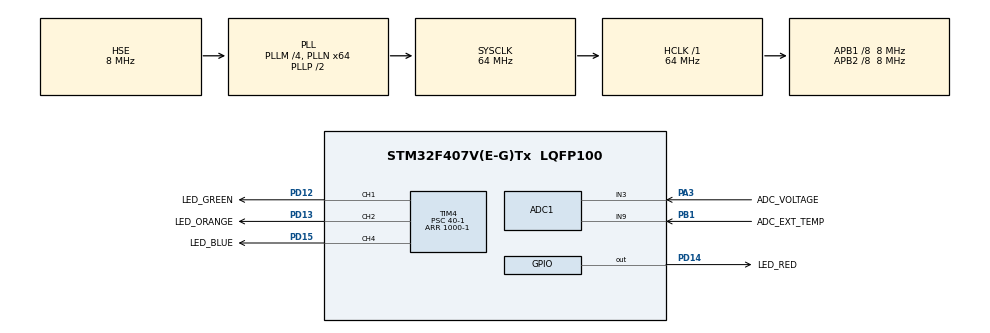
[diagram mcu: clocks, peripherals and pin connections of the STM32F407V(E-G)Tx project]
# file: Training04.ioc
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ADC1.Channel-0\#ChannelRegularConversion=ADC_CHANNEL_3
ADC1.Channel-3\#ChannelRegularConversion=ADC_CHANNEL_TEMPSENSOR
ADC1.Channel-4\#ChannelRegularConversion=ADC_CHANNEL_9
ADC1.ClockPrescaler=ADC_CLOCK_SYNC_PCLK_DIV8
ADC1.ContinuousConvMode=ENABLE
ADC1.EnableAnalogWatchDog=false
ADC1.InjNumberOfConversion=0
ADC1.NbrOfConversion=3
ADC1.NbrOfConversionFlag=1
ADC1.Rank-0\#ChannelRegularConversion=1
ADC1.Rank-3\#ChannelRegularConversion=2
ADC1.Rank-4\#ChannelRegularConversion=3
ADC1.SamplingTime-0\#ChannelRegularConversion=ADC_SAMPLETIME_480CYCLES
ADC1.SamplingTime-3\#ChannelRegularConversion=ADC_SAMPLETIME_56CYCLES
ADC1.SamplingTime-4\#ChannelRegularConversion=ADC_SAMPLETIME_112CYCLES
ADC1.master=1
Mcu.Family=STM32F4
Mcu.Name=STM32F407V(E-G)Tx
Mcu.Package=LQFP100
NVIC.PriorityGroup=NVIC_PRIORITYGROUP_4
NVIC.TIM6_DAC_IRQn=true\:0\:0\:false\:false\:true\:true\:true\:true
PA3.GPIO_Label=ADC_VOLTAGE
PA3.Signal=ADCx_IN3
PB1.GPIO_Label=ADC_EXT_TEMP
PB1.Signal=ADCx_IN9
PD12.GPIO_Label=LED_GREEN
PD12.GPIO_ModeDefaultPP=GPIO_MODE_AF_PP
PD12.GPIO_PuPd=GPIO_PULLDOWN
PD12.GPIO_Speed=GPIO_SPEED_FREQ_HIGH
PD12.Signal=S_TIM4_CH1
PD13.GPIO_Label=LED_ORANGE
PD13.GPIO_ModeDefaultPP=GPIO_MODE_AF_PP
PD13.GPIO_PuPd=GPIO_PULLDOWN
PD13.GPIO_Speed=GPIO_SPEED_FREQ_HIGH
PD13.Signal=S_TIM4_CH2
PD14.GPIO_Label=LED_RED
PD14.Signal=GPIO_Output
PD15.GPIO_Label=LED_BLUE
PD15.GPIO_ModeDefaultPP=GPIO_MODE_AF_PP
PD15.GPIO_PuPd=GPIO_PULLDOWN
PD15.GPIO_Speed=GPIO_SPEED_FREQ_HIGH
PD15.Signal=S_TIM4_CH4
PH0-OSC_IN.Mode=HSE-External-Oscillator
PH0-OSC_IN.Signal=RCC_OSC_IN
PH1-OSC_OUT.Mode=HSE-External-Oscillator
PH1-OSC_OUT.Signal=RCC_OSC_OUT
ProjectManager.HeapSize=0x200
ProjectManager.StackSize=0x400
ProjectManager.TargetToolchain=STM32CubeIDE
RCC.48MHZClocksFreq_Value=32000000
RCC.AHBFreq_Value=64000000
RCC.APB1CLKDivider=RCC_HCLK_DIV8
RCC.APB1Freq_Value=8000000
RCC.APB1TimFreq_Value=16000000
RCC.APB2CLKDivider=RCC_HCLK_DIV8
RCC.APB2Freq_Value=8000000
RCC.APB2TimFreq_Value=16000000
RCC.CortexFreq_Value=64000000
RCC.HCLKFreq_Value=64000000
RCC.HSE_VALUE=8000000
RCC.HSI_VALUE=16000000
RCC.LSE_VALUE=32768
RCC.PLLM=4
RCC.PLLN=64
RCC.PLLSourceVirtual=RCC_PLLSOURCE_HSE
RCC.SYSCLKFreq_VALUE=64000000
RCC.SYSCLKSource=RCC_SYSCLKSOURCE_PLLCLK
RCC.VCOOutputFreq_Value=128000000
SH.ADCx_IN3.0=ADC1_IN3,IN3
SH.ADCx_IN9.0=ADC1_IN9,IN9
SH.S_TIM4_CH1.0=TIM4_CH1,PWM Generation1 CH1
SH.S_TIM4_CH2.0=TIM4_CH2,PWM Generation2 CH2
SH.S_TIM4_CH4.0=TIM4_CH4,PWM Generation4 CH4
TIM4.AutoReloadPreload=TIM_AUTORELOAD_PRELOAD_ENABLE
TIM4.Channel-PWM\ Generation1\ CH1=TIM_CHANNEL_1
TIM4.Channel-PWM\ Generation2\ CH2=TIM_CHANNEL_2
TIM4.Channel-PWM\ Generation4\ CH4=TIM_CHANNEL_4
TIM4.Period=1000-1
TIM4.Prescaler=40-1
TIM6.AutoReloadPreload=TIM_AUTORELOAD_PRELOAD_ENABLE
TIM6.Period=200-1
TIM6.Prescaler=16000-1
VP_ADC1_TempSens_Input.Mode=IN-TempSens
VP_TIM4_VS_ClockSourceINT.Mode=Internal
VP_TIM6_VS_ClockSourceINT.Mode=Enable_Timer
board=custom

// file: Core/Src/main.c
/* USER CODE BEGIN Header */
/**
  ******************************************************************************
  * @file           : main.c
  * @brief          : Main program body
  ******************************************************************************
  * @attention
  *
  * Copyright (c) 2023 STMicroelectronics.
  * All rights reserved.
  *
  * This software is licensed under terms that can be found in the LICENSE file
  * in the root directory of this software component.
  * If no LICENSE file comes with this software, it is provided AS-IS.
  *
  ******************************************************************************
  */
/* USER CODE END Header */
#include "main.h"

ADC_HandleTypeDef hadc1;

TIM_HandleTypeDef htim4;
TIM_HandleTypeDef htim6;

/* USER CODE BEGIN PV */
PWM TIMERSETTINGS={400,{0}};
PWM* pTIMERSETTINGS=&TIMERSETTINGS;
volatile uint32_t counter =0;
/* USER CODE END PV */

void SystemClock_Config(void);
static void MX_GPIO_Init(void);
static void MX_ADC1_Init(void);
static void MX_TIM4_Init(void);
static void MX_TIM6_Init(void);

int main(void)
{

  /* MCU Configuration--------------------------------------------------------*/

  /* Reset of all peripherals, Initializes the Flash interface and the Systick. */
  HAL_Init();

  /* Configure the system clock */
  SystemClock_Config();

  /* Initialize all configured peripherals */
  MX_GPIO_Init();
  MX_ADC1_Init();
  MX_TIM4_Init();
  MX_TIM6_Init();

  /* Infinite loop */
  /* USER CODE BEGIN WHILE */
  HAL_TIM_Base_Start_IT(&htim6);
 while (1)
  {
    static uint32_t temp=0;
    if (counter-temp>100||counter<temp)
      {
	   HandleAdcChannels(pTIMERSETTINGS);
	   temp=counter;
      }

    /* USER CODE END WHILE */

  }
}

void SystemClock_Config(void)
{
  RCC_OscInitTypeDef RCC_OscInitStruct = {0};
  RCC_ClkInitTypeDef RCC_ClkInitStruct = {0};

  /** Configure the main internal regulator output voltage
  */
  __HAL_RCC_PWR_CLK_ENABLE();
  __HAL_PWR_VOLTAGESCALING_CONFIG(PWR_REGULATOR_VOLTAGE_SCALE1);

  /** Initializes the RCC Oscillators according to the specified parameters
  * in the RCC_OscInitTypeDef structure.
  */
  RCC_OscInitStruct.OscillatorType = RCC_OSCILLATORTYPE_HSE;
  RCC_OscInitStruct.HSEState = RCC_HSE_ON;
  RCC_OscInitStruct.PLL.PLLState = RCC_PLL_ON;
  RCC_OscInitStruct.PLL.PLLSource = RCC_PLLSOURCE_HSE;
  RCC_OscInitStruct.PLL.PLLM = 4;
  RCC_OscInitStruct.PLL.PLLN = 64;
  RCC_OscInitStruct.PLL.PLLP = RCC_PLLP_DIV2;
  RCC_OscInitStruct.PLL.PLLQ = 4;
  if (HAL_RCC_OscConfig(&RCC_OscInitStruct) != HAL_OK)
  {
    Error_Handler();
  }

  /** Initializes the CPU, AHB and APB buses clocks
  */
  RCC_ClkInitStruct.ClockType = RCC_CLOCKTYPE_HCLK|RCC_CLOCKTYPE_SYSCLK
                              |RCC_CLOCKTYPE_PCLK1|RCC_CLOCKTYPE_PCLK2;
  RCC_ClkInitStruct.SYSCLKSource = RCC_SYSCLKSOURCE_PLLCLK;
  RCC_ClkInitStruct.AHBCLKDivider = RCC_SYSCLK_DIV1;
  RCC_ClkInitStruct.APB1CLKDivider = RCC_HCLK_DIV8;
  RCC_ClkInitStruct.APB2CLKDivider = RCC_HCLK_DIV8;

  if (HAL_RCC_ClockConfig(&RCC_ClkInitStruct, FLASH_LATENCY_2) != HAL_OK)
  {
    Error_Handler();
  }
}

static void MX_ADC1_Init(void)
{

  ADC_ChannelConfTypeDef sConfig = {0};

  /** Configure the global features of the ADC (Clock, Resolution, Data Alignment and number of conversion)
  */
  hadc1.Instance = ADC1;
  hadc1.Init.ClockPrescaler = ADC_CLOCK_SYNC_PCLK_DIV8;
  hadc1.Init.Resolution = ADC_RESOLUTION_12B;
  hadc1.Init.ScanConvMode = ENABLE;
  hadc1.Init.ContinuousConvMode = ENABLE;
  hadc1.Init.DiscontinuousConvMode = DISABLE;
  hadc1.Init.ExternalTrigConvEdge = ADC_EXTERNALTRIGCONVEDGE_NONE;
  hadc1.Init.ExternalTrigConv = ADC_SOFTWARE_START;
  hadc1.Init.DataAlign = ADC_DATAALIGN_RIGHT;
  hadc1.Init.NbrOfConversion = 3;
  hadc1.Init.DMAContinuousRequests = DISABLE;
  hadc1.Init.EOCSelection = ADC_EOC_SINGLE_CONV;
  if (HAL_ADC_Init(&hadc1) != HAL_OK)
  {
    Error_Handler();
  }

  /** Configure for the selected ADC regular channel its corresponding rank in the sequencer and its sample time.
  */
  sConfig.Channel = ADC_CHANNEL_3;
  sConfig.Rank = 1;
  sConfig.SamplingTime = ADC_SAMPLETIME_480CYCLES;
  if (HAL_ADC_ConfigChannel(&hadc1, &sConfig) != HAL_OK)
  {
    Error_Handler();
  }

  /** Configure for the selected ADC regular channel its corresponding rank in the sequencer and its sample time.
  */
  sConfig.Channel = ADC_CHANNEL_TEMPSENSOR;
  sConfig.Rank = 2;
  sConfig.SamplingTime = ADC_SAMPLETIME_56CYCLES;
  if (HAL_ADC_ConfigChannel(&hadc1, &sConfig) != HAL_OK)
  {
    Error_Handler();
  }

  /** Configure for the selected ADC regular channel its corresponding rank in the sequencer and its sample time.
  */
  sConfig.Channel = ADC_CHANNEL_9;
  sConfig.Rank = 3;
  sConfig.SamplingTime = ADC_SAMPLETIME_112CYCLES;
  if (HAL_ADC_ConfigChannel(&hadc1, &sConfig) != HAL_OK)
  {
    Error_Handler();
  }

}

static void MX_TIM4_Init(void)
{

  TIM_ClockConfigTypeDef sClockSourceConfig = {0};
  TIM_MasterConfigTypeDef sMasterConfig = {0};
  TIM_OC_InitTypeDef sConfigOC = {0};

  htim4.Instance = TIM4;
  htim4.Init.Prescaler = 40-1;
  htim4.Init.CounterMode = TIM_COUNTERMODE_UP;
  htim4.Init.Period = 1000-1;
  htim4.Init.ClockDivision = TIM_CLOCKDIVISION_DIV1;
  htim4.Init.AutoReloadPreload = TIM_AUTORELOAD_PRELOAD_ENABLE;
  if (HAL_TIM_Base_Init(&htim4) != HAL_OK)
  {
    Error_Handler();
  }
  sClockSourceConfig.ClockSource = TIM_CLOCKSOURCE_INTERNAL;
  if (HAL_TIM_ConfigClockSource(&htim4, &sClockSourceConfig) != HAL_OK)
  {
    Error_Handler();
  }
  if (HAL_TIM_PWM_Init(&htim4) != HAL_OK)
  {
    Error_Handler();
  }
  sMasterConfig.MasterOutputTrigger = TIM_TRGO_RESET;
  sMasterConfig.MasterSlaveMode = TIM_MASTERSLAVEMODE_DISABLE;
  if (HAL_TIMEx_MasterConfigSynchronization(&htim4, &sMasterConfig) != HAL_OK)
  {
    Error_Handler();
  }
  sConfigOC.OCMode = TIM_OCMODE_PWM1;
  sConfigOC.Pulse = 0;
  sConfigOC.OCPolarity = TIM_OCPOLARITY_HIGH;
  sConfigOC.OCFastMode = TIM_OCFAST_DISABLE;
  if (HAL_TIM_PWM_ConfigChannel(&htim4, &sConfigOC, TIM_CHANNEL_1) != HAL_OK)
  {
    Error_Handler();
  }
  if (HAL_TIM_PWM_ConfigChannel(&htim4, &sConfigOC, TIM_CHANNEL_2) != HAL_OK)
  {
    Error_Handler();
  }
  if (HAL_TIM_PWM_ConfigChannel(&htim4, &sConfigOC, TIM_CHANNEL_4) != HAL_OK)
  {
    Error_Handler();
  }
  HAL_TIM_MspPostInit(&htim4);

}

static void MX_TIM6_Init(void)
{

  TIM_MasterConfigTypeDef sMasterConfig = {0};

  htim6.Instance = TIM6;
  htim6.Init.Prescaler = 16000-1;
  htim6.Init.CounterMode = TIM_COUNTERMODE_UP;
  htim6.Init.Period = 200-1;
  htim6.Init.AutoReloadPreload = TIM_AUTORELOAD_PRELOAD_ENABLE;
  if (HAL_TIM_Base_Init(&htim6) != HAL_OK)
  {
    Error_Handler();
  }
  sMasterConfig.MasterOutputTrigger = TIM_TRGO_RESET;
  sMasterConfig.MasterSlaveMode = TIM_MASTERSLAVEMODE_DISABLE;
  if (HAL_TIMEx_MasterConfigSynchronization(&htim6, &sMasterConfig) != HAL_OK)
  {
    Error_Handler();
  }

}

static void MX_GPIO_Init(void)
{
  GPIO_InitTypeDef GPIO_InitStruct = {0};

  /* GPIO Ports Clock Enable */
  __HAL_RCC_GPIOH_CLK_ENABLE();
  __HAL_RCC_GPIOA_CLK_ENABLE();
  __HAL_RCC_GPIOB_CLK_ENABLE();
  __HAL_RCC_GPIOD_CLK_ENABLE();

  /*Configure GPIO pin Output Level */
  HAL_GPIO_WritePin(LED_RED_GPIO_Port, LED_RED_Pin, GPIO_PIN_RESET);

  /*Configure GPIO pin : LED_RED_Pin */
  GPIO_InitStruct.Pin = LED_RED_Pin;
  GPIO_InitStruct.Mode = GPIO_MODE_OUTPUT_PP;
  GPIO_InitStruct.Pull = GPIO_NOPULL;
  GPIO_InitStruct.Speed = GPIO_SPEED_FREQ_LOW;
  HAL_GPIO_Init(LED_RED_GPIO_Port, &GPIO_InitStruct);

}

/* USER CODE BEGIN 4 */

/*
void HAL_ADC_ConvCpltCallback(ADC_HandleTypeDef* hadc)
{
	  //adcValue[adcId] = HAL_ADC_GetValue(&hadc1);

	if (adcId==0) adcValue0=HAL_ADC_GetValue(&hadc1);
	if (adcId==1) adcValue1=HAL_ADC_GetValue(&hadc1);
	if (adcId==2) adcValue2=HAL_ADC_GetValue(&hadc1);
	  adcId = (adcId + 1) % 3;                     //so, it can be 0, 1 or 2 only
}
*/
/* USER CODE END 4 */

void Error_Handler(void)
{
  __disable_irq();
  while (1)
  {
  }
}
